# LPC55S6x register map
Vendor: nxp.com; File version: 1.0
CPU: CM33 r2p0, little endian, MPU, FPU, VTOR, 3 interrupt priority bits
Registers are 32-bit, read-write, reset 0x0 unless marked. A register's access mark holds for its fields unless they carry their own. Offsets are from the block's base; [hi:lo] are bit positions; lines under a group give offsets from that group; {n}, {i} and the like mark numbered series; 'fields as' and 'values as' point back to an identical list.

## FLASH_KEY_STORE
Base 0x0009E600
0x00 HEADER — Valid Key Sore Header : 0x95959595
  [31:0] FIELD
0x04 puf_discharge_time_in_ms
  [31:0] FIELD
{0x8+4i} ACTIVATION_CODE[{i}] (i=0..297)
  [31:0] FIELD
0x4B0 SBKEY_HEADER0 (SBKEY_KEY_CODE view)
  [31:0] FIELD
{0x4B0+4i} SBKEY_KEY_CODE{i} (SBKEY_KEY_CODE view) (i=0..13)
  [31:0] FIELD
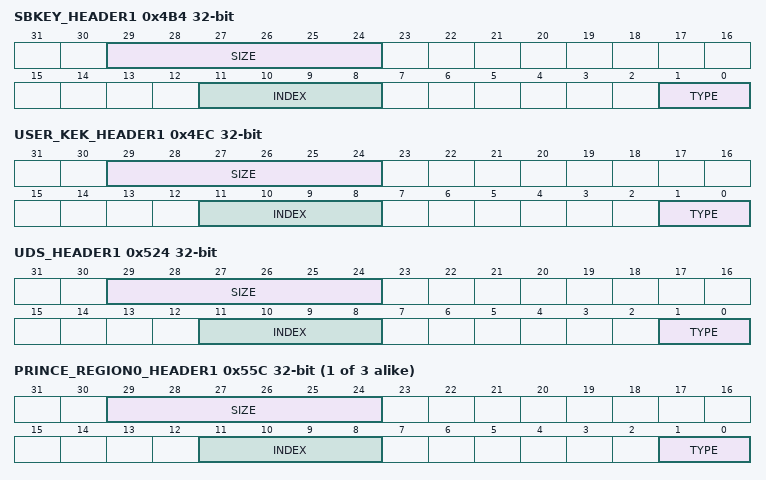
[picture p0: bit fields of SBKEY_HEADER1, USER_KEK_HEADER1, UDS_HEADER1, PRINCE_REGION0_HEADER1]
0x4B4 SBKEY_HEADER1 (SBKEY_KEY_CODE view)
  [29:24] SIZE, [11:8] INDEX, [1:0] TYPE
{0x4B8+4i} SBKEY_BODY{i} (SBKEY_KEY_CODE view) (i=0..11)
  [31:0] FIELD
0x4E8 USER_KEK_HEADER0 (USER_KEK_KEY_CODE view)
  [31:0] FIELD
{0x4E8+4i} USER_KEK_KEY_CODE{i} (USER_KEK_KEY_CODE view) (i=0..13)
  [31:0] FIELD
0x4EC USER_KEK_HEADER1 (USER_KEK_KEY_CODE view)
  [29:24] SIZE, [11:8] INDEX, [1:0] TYPE
{0x4F0+4i} USER_KEK_BODY{i} (USER_KEK_KEY_CODE view) (i=0..11)
  [31:0] FIELD
0x520 UDS_HEADER0 (UDS_KEY_CODE view)
  [31:0] FIELD
{0x520+4i} UDS_KEY_CODE{i} (UDS_KEY_CODE view) (i=0..13)
  [31:0] FIELD
0x524 UDS_HEADER1 (UDS_KEY_CODE view)
  [29:24] SIZE, [11:8] INDEX, [1:0] TYPE
{0x528+4i} UDS_BODY{i} (UDS_KEY_CODE view) (i=0..11)
  [31:0] FIELD
{0x558+0x38*i} PRINCE_REGION{i}_HEADER0 (PRINCE_REGION{i}_KEY_CODE view) (i=0..2)
  [31:0] FIELD
{0x558+4i} PRINCE_REGION0_KEY_CODE{i} (PRINCE_REGION0_KEY_CODE view) (i=0..13)
  [31:0] FIELD
{0x55C+0x38*i} PRINCE_REGION{i}_HEADER1 (PRINCE_REGION{i}_KEY_CODE view) (i=0..2)
  [29:24] SIZE, [11:8] INDEX, [1:0] TYPE
{0x560+4i} PRINCE_REGION0_BODY{i} (PRINCE_REGION0_KEY_CODE view) (i=0..11)
  [31:0] FIELD
{0x590+4i} PRINCE_REGION1_KEY_CODE{i} (PRINCE_REGION1_KEY_CODE view) (i=0..13)
  [31:0] FIELD
{0x598+4i} PRINCE_REGION1_BODY{i} (PRINCE_REGION1_KEY_CODE view) (i=0..11)
  [31:0] FIELD
{0x5C8+4i} PRINCE_REGION2_KEY_CODE{i} (PRINCE_REGION2_KEY_CODE view) (i=0..13)
  [31:0] FIELD
{0x5D0+4i} PRINCE_REGION2_BODY{i} (PRINCE_REGION2_KEY_CODE view) (i=0..11)
  [31:0] FIELD

## IOCON — I/O pin configuration (IOCON)
Base 0x40001000
0x00 P0[{i}] (i=0..31; step ?) group — Digital I/O control for port 0
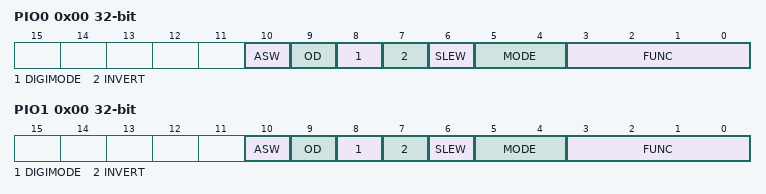
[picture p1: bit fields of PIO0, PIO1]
  0x00 PIO0
    [10] ASW — Analog switch input control.
      0=For pins PIO0_9, PIO0_11, PIO0_12, PIO0_15, PIO0_18, PIO0_31, PIO1_0 and PIO1_9, analog switch is closed (enabled). For the other pins, analog switch is open (disabled).; 1=For all pins except PIO0_9, PIO0_11, PIO0_12, PIO0_15, PIO0_18, PIO0_31, PIO1_0 and PIO1_9 analog switch is closed (enabled)
    [9] OD — Controls open-drain mode.
      0=NORMAL (Normal. Normal push-pull output); 1=OPEN_DRAIN (Open-drain. Simulated open-drain output (high drive disabled).)
    [8] DIGIMODE — Select Digital mode.
      0=ANALOG (Disable digital mode. Digital input set to 0.); 1=DIGITAL (Enable Digital mode. Digital input is enabled.)
    [7] INVERT — Input polarity.
      0=DISABLED (Disabled. Input function is not inverted.); 1=ENABLED (Enabled. Input is function inverted.)
    [6] SLEW — Driver slew rate.
      0=STANDARD (Standard-mode, output slew rate is slower. More outputs can be switched simultaneously.); 1=FAST (Fast-mode, output slew rate is faster. Refer to the appropriate specific device data sheet for details.)
    [5:4] MODE — Selects function mode (on-chip pull-up/pull-down resistor control).
      0=INACTIVE (Inactive. Inactive (no pull-down/pull-up resistor enabled).); 1=PULL_DOWN (Pull-down. Pull-down resistor enabled.); 2=PULL_UP (Pull-up. Pull-up resistor enabled.); 3=REPEATER (Repeater. Repeater mode.)
    [3:0] FUNC — Selects pin function.
      {v}=ALT{v} (Alternative connection {v}.) (v=0..7)
0x80 P1[{i}] (i=0..31; step ?) group — Digital I/O control for port 1
  0x00 PIO1
    fields as P0[{i}].PIO0

## GINT0 — Group GPIO input interrupt (GINT0/1)
Base 0x40002000
Same registers: GINT1 0x40003000
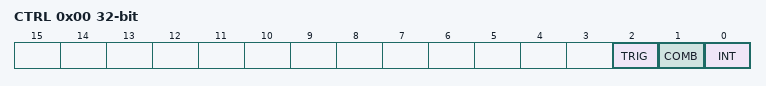
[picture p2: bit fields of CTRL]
0x00 CTRL — GPIO grouped interrupt control register
  [2] TRIG — Group interrupt trigger
    0=EDGE_TRIGGERED; 1=LEVEL_TRIGGERED
  [1] COMB — Combine enabled inputs for group interrupt
    0=OR (Or. OR functionality: A grouped interrupt is generated when any one of the enabled inputs is active (based on its programmed polarity).); 1=AND (And. AND functionality: An interrupt is generated when all enabled bits are active (based on their programmed polarity).)
  [0] INT — Group interrupt status. This bit is cleared by writing a one to it. Writing zero has no effect.
    0=NO_REQUEST (No request. No interrupt request is pending.); 1=REQUEST_ACTIVE (Request active. Interrupt request is active.)
{0x20+4i} PORT_POL[{i}] (i=0..1) reset 0xFFFFFFFF — GPIO grouped interrupt port 0 polarity register
  [31:0] POL — Configure pin polarity of port m pins for group interrupt. Bit n corresponds to pin PIOm_n of port m. 0 = the pin is active LOW. If the level on this pin is LOW, the pin contributes to the group interrupt. 1 = the pin is active HIGH. If the level on this pin is HIGH, the pin contributes to the group interrupt.
{0x40+4i} PORT_ENA[{i}] (i=0..1) — GPIO grouped interrupt port 0 enable register
  [31:0] ENA — Enable port 0 pin for group interrupt. Bit n corresponds to pin Pm_n of port m. 0 = the port 0 pin is disabled and does not contribute to the grouped interrupt. 1 = the port 0 pin is enabled and contributes to the grouped interrupt.

## Notices in the file
Copyright 2016-2019 NXP
All rights reserved.
SPDX-License-Identifier: BSD-3-Clause
